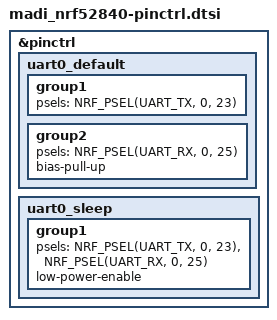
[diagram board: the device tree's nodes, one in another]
/*
 * SPDX-FileCopyrightText: 2026 Kyunghwan Kwon <k@libmcu.org>
 *
 * SPDX-License-Identifier: MIT
 *
 * Pin assignments for MADI nRF52840:
 *   UART0 TX  : P0.23
 *   UART0 RX  : P0.25
 *   LED       : P0.20  (gpio-leds node, not pinctrl)
 */

&pinctrl {
	uart0_default: uart0_default {
		group1 {
			psels = <NRF_PSEL(UART_TX, 0, 23)>;
		};
		group2 {
			psels = <NRF_PSEL(UART_RX, 0, 25)>;
			bias-pull-up;
		};
	};

	uart0_sleep: uart0_sleep {
		group1 {
			psels = <NRF_PSEL(UART_TX, 0, 23)>,
			        <NRF_PSEL(UART_RX, 0, 25)>;
			low-power-enable;
		};
	};
};
